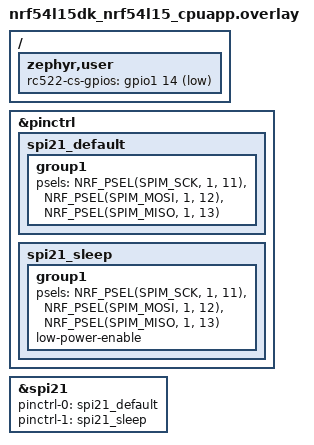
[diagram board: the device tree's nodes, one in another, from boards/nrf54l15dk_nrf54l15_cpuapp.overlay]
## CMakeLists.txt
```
cmake_minimum_required(VERSION 3.20.0)
find_package(Zephyr REQUIRED HINTS $ENV{ZEPHYR_BASE})
project(rune_nfc_uid_reader)

target_sources(app PRIVATE src/main.c src/rc522.c src/pn532.c)
```

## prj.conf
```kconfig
CONFIG_GPIO=y
CONFIG_SPI=y
CONFIG_I2C=y
CONFIG_PRINTK=y
CONFIG_CONSOLE=y
CONFIG_UART_CONSOLE=y
CONFIG_MAIN_STACK_SIZE=2048
```

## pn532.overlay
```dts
/*
 * Alternative wiring: PN532 reader on I2C21.
 * Use it by adding this file as an "Extra Devicetree overlay" in the
 * VS Code build configuration (or: west build ... -- -DEXTRA_DTC_OVERLAY_FILE=pn532.overlay).
 *
 * Set the PN532 module's switches to I2C mode (red "PN532 NFC V3" board:
 * switch 1 = ON, switch 2 = OFF), then power-cycle it.
 *
 *   PN532 pin  ->  nRF54L15 DK pin
 *   SCL        ->  P1.11
 *   SDA        ->  P1.12
 *   VCC        ->  VDD (3.3 V)
 *   GND        ->  GND
 *
 * IMPORTANT: set the DK's VDD to 3.3 V in nRF Connect "Board Configurator".
 */

&spi21 {
	status = "disabled";
};

&pinctrl {
	i2c21_default: i2c21_default {
		group1 {
			psels = <NRF_PSEL(TWIM_SCL, 1, 11)>,
				<NRF_PSEL(TWIM_SDA, 1, 12)>;
			bias-pull-up;
		};
	};

	i2c21_sleep: i2c21_sleep {
		group1 {
			psels = <NRF_PSEL(TWIM_SCL, 1, 11)>,
				<NRF_PSEL(TWIM_SDA, 1, 12)>;
			low-power-enable;
		};
	};
};

&i2c21 {
	status = "okay";
	pinctrl-0 = <&i2c21_default>;
	pinctrl-1 = <&i2c21_sleep>;
	pinctrl-names = "default", "sleep";
	clock-frequency = <I2C_BITRATE_STANDARD>;
};
```

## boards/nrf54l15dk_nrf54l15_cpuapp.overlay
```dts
/*
 * Default wiring: MFRC522 ("RC522") reader on SPI21.
 *
 *   RC522 pin   ->  nRF54L15 DK pin
 *   SDA (=CS)   ->  P1.14
 *   SCK         ->  P1.11
 *   MOSI        ->  P1.12
 *   MISO        ->  P1.13   (shared with Button 0: don't press Button 0)
 *   RST         ->  VDD (3.3 V)  (just keep the chip out of reset)
 *   3.3V        ->  VDD
 *   GND         ->  GND
 *   IRQ         ->  not connected
 *
 * IMPORTANT: set the DK's VDD to 3.3 V in nRF Connect "Board Configurator"
 * first. The RC522 cannot see 1.8 V logic.
 */

/ {
	zephyr,user {
		rc522-cs-gpios = <&gpio1 14 GPIO_ACTIVE_LOW>;
	};
};

&pinctrl {
	spi21_default: spi21_default {
		group1 {
			psels = <NRF_PSEL(SPIM_SCK, 1, 11)>,
				<NRF_PSEL(SPIM_MOSI, 1, 12)>,
				<NRF_PSEL(SPIM_MISO, 1, 13)>;
		};
	};

	spi21_sleep: spi21_sleep {
		group1 {
			psels = <NRF_PSEL(SPIM_SCK, 1, 11)>,
				<NRF_PSEL(SPIM_MOSI, 1, 12)>,
				<NRF_PSEL(SPIM_MISO, 1, 13)>;
			low-power-enable;
		};
	};
};

&spi21 {
	status = "okay";
	pinctrl-0 = <&spi21_default>;
	pinctrl-1 = <&spi21_sleep>;
	pinctrl-names = "default", "sleep";
};
```

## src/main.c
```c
/*
 * Rune board, step 1: read the ID (UID) of an NFC tag and print it.
 *
 * Output on the DK's USB serial port (115200 baud):
 *   TAG 04A1B2C3D4E5F6     when a tag is placed on the reader
 *   REMOVED                when it is taken away
 * LED0 is on while a tag is on the reader.
 */
#include <zephyr/kernel.h>
#include <zephyr/devicetree.h>
#include <zephyr/drivers/gpio.h>
#include <zephyr/sys/printk.h>
#include <string.h>
#include "nfc_reader.h"

#define POLL_MS     100
#define MISSES_GONE 3   /* polls without the tag before we call it removed */

static const struct gpio_dt_spec led = GPIO_DT_SPEC_GET(DT_ALIAS(led0), gpios);

static void print_uid(const uint8_t *uid, int len)
{
	printk("TAG ");
	for (int i = 0; i < len; i++) {
		printk("%02X", uid[i]);
	}
	printk("\n");
}

int main(void)
{
	uint8_t uid[10], last_uid[10];
	int last_len = 0;
	int misses = 0;

	gpio_pin_configure_dt(&led, GPIO_OUTPUT_INACTIVE);
	printk("\nRune NFC UID reader, using %s\n", nfc_reader_name());

	while (nfc_reader_init() != 0) {
		printk("Reader not found. Check wiring and that VDD is 3.3 V. Retrying...\n");
		k_msleep(2000);
	}
	printk("Reader ready. Put a tag on it.\n");

	while (true) {
		int len = nfc_reader_poll(uid, sizeof(uid));

		if (len > 0) {
			misses = 0;
			if (len != last_len || memcmp(uid, last_uid, len) != 0) {
				print_uid(uid, len);
				memcpy(last_uid, uid, len);
				last_len = len;
				gpio_pin_set_dt(&led, 1);
			}
		} else if (last_len > 0 && ++misses >= MISSES_GONE) {
			printk("REMOVED\n");
			last_len = 0;
			gpio_pin_set_dt(&led, 0);
		}
		k_msleep(POLL_MS);
	}
	return 0;
}
```

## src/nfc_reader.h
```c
#ifndef NFC_READER_H_
#define NFC_READER_H_

#include <stddef.h>
#include <stdint.h>

/* The PN532 driver is used when i2c21 is enabled (pn532.overlay), otherwise RC522. */
#define USE_PN532 DT_NODE_HAS_STATUS(DT_NODELABEL(i2c21), okay)

/* Returns 0 on success, negative errno if the reader does not answer. */
int nfc_reader_init(void);

/*
 * Looks for one ISO14443-A tag (NTAG, MIFARE Ultralight/Classic, ...).
 * Returns the UID length (4, 7 or 10) and fills uid, or 0 if no tag is there.
 */
int nfc_reader_poll(uint8_t *uid, size_t max_len);

const char *nfc_reader_name(void);

#endif
```

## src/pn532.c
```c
/* Minimal PN532 driver over I2C: reads the UID of one ISO14443-A tag. */
#include <zephyr/devicetree.h>
#include "nfc_reader.h"

#if USE_PN532

#include <errno.h>
#include <string.h>
#include <zephyr/kernel.h>
#include <zephyr/drivers/i2c.h>
#include <zephyr/sys/printk.h>

#define PN532_ADDR 0x24

static const struct device *i2c = DEVICE_DT_GET(DT_NODELABEL(i2c21));

static int write_frame(const uint8_t *data, size_t len)
{
	uint8_t f[40];
	size_t i = 0;
	uint8_t l = (uint8_t)(len + 1);
	uint8_t sum = 0xD4;

	if (len > sizeof(f) - 9) {
		return -EINVAL;
	}
	f[i++] = 0x00;
	f[i++] = 0x00;
	f[i++] = 0xFF;
	f[i++] = l;
	f[i++] = (uint8_t)(~l + 1);
	f[i++] = 0xD4; /* host -> PN532 */
	for (size_t j = 0; j < len; j++) {
		f[i++] = data[j];
		sum += data[j];
	}
	f[i++] = (uint8_t)(~sum + 1);
	f[i++] = 0x00;
	return i2c_write(i2c, f, i, PN532_ADDR);
}

static int wait_ready(int timeout_ms)
{
	int64_t end = k_uptime_get() + timeout_ms;
	uint8_t status;

	while (k_uptime_get() < end) {
		if (i2c_read(i2c, &status, 1, PN532_ADDR) == 0 && (status & 0x01)) {
			return 0;
		}
		k_msleep(2);
	}
	return -ETIMEDOUT;
}

/* Sends a command, returns number of response data bytes copied to resp (after D5 cmd+1). */
static int command(const uint8_t *cmd, size_t len, uint8_t *resp, size_t rmax, int timeout_ms)
{
	static const uint8_t ack_ok[6] = { 0x00, 0x00, 0xFF, 0x00, 0xFF, 0x00 };
	uint8_t ack[7];
	uint8_t buf[48];

	if (write_frame(cmd, len)) {
		return -EIO;
	}
	if (wait_ready(30)) {
		return -ETIMEDOUT;
	}
	if (i2c_read(i2c, ack, sizeof(ack), PN532_ADDR) || memcmp(&ack[1], ack_ok, 6)) {
		return -EIO;
	}
	if (wait_ready(timeout_ms)) {
		return -ETIMEDOUT;
	}
	if (i2c_read(i2c, buf, sizeof(buf), PN532_ADDR)) {
		return -EIO;
	}
	/* buf: status, 00 00 FF, LEN, LCS, D5, cmd+1, data... */
	if (buf[1] != 0x00 || buf[2] != 0x00 || buf[3] != 0xFF) {
		return -EIO;
	}
	if (buf[6] != 0xD5 || buf[7] != (uint8_t)(cmd[0] + 1) || buf[4] < 2) {
		return -EIO;
	}

	size_t dlen = buf[4] - 2;

	if (dlen > sizeof(buf) - 8) {
		dlen = sizeof(buf) - 8;
	}
	if (dlen > rmax) {
		dlen = rmax;
	}
	memcpy(resp, &buf[8], dlen);
	return (int)dlen;
}

int nfc_reader_init(void)
{
	uint8_t resp[8];
	int n = -1;

	if (!device_is_ready(i2c)) {
		return -ENODEV;
	}

	/* The first transfer may only wake the chip up, so retry. */
	for (int i = 0; i < 5 && n < 0; i++) {
		static const uint8_t get_fw[] = { 0x02 };

		n = command(get_fw, sizeof(get_fw), resp, sizeof(resp), 100);
		if (n < 0) {
			k_msleep(50);
		}
	}
	if (n < 4) {
		return -EIO;
	}
	printk("PN5%02X firmware %d.%d\n", resp[0], resp[1], resp[2]);

	static const uint8_t sam[] = { 0x14, 0x01, 0x14, 0x01 };       /* SAMConfiguration: normal */
	static const uint8_t retries[] = { 0x32, 0x05, 0xFF, 0x01, 0x02 }; /* don't wait forever for a tag */

	if (command(sam, sizeof(sam), resp, sizeof(resp), 100) < 0 ||
	    command(retries, sizeof(retries), resp, sizeof(resp), 100) < 0) {
		return -EIO;
	}
	return 0;
}

int nfc_reader_poll(uint8_t *uid, size_t max_len)
{
	static const uint8_t field_off[] = { 0x32, 0x01, 0x00 };
	static const uint8_t field_on[] = { 0x32, 0x01, 0x03 };
	static const uint8_t list[] = { 0x4A, 0x01, 0x00 }; /* 1 target, 106 kbps type A */
	uint8_t resp[24];

	/* Switch the field off and on so a tag that stays on the reader is seen again. */
	command(field_off, sizeof(field_off), resp, sizeof(resp), 50);
	k_msleep(5);
	command(field_on, sizeof(field_on), resp, sizeof(resp), 50);

	int n = command(list, sizeof(list), resp, sizeof(resp), 200);

	/* resp: NbTg, Tg, ATQA(2), SAK, UIDlen, UID... */
	if (n < 6 || resp[0] == 0) {
		return 0;
	}

	size_t len = resp[5];

	if (len > max_len || 6 + len > (size_t)n) {
		return 0;
	}
	memcpy(uid, &resp[6], len);
	return (int)len;
}

const char *nfc_reader_name(void)
{
	return "PN532 (I2C)";
}

#endif /* USE_PN532 */
```

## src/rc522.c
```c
/* Minimal MFRC522 (RC522) driver: reads the UID of one ISO14443-A tag. */
#include <zephyr/devicetree.h>
#include "nfc_reader.h"

#if !USE_PN532

#include <errno.h>
#include <zephyr/kernel.h>
#include <zephyr/drivers/spi.h>
#include <zephyr/drivers/gpio.h>
#include <zephyr/sys/printk.h>

/* Registers */
#define CommandReg    0x01
#define ComIrqReg     0x04
#define DivIrqReg     0x05
#define ErrorReg      0x06
#define FIFODataReg   0x09
#define FIFOLevelReg  0x0A
#define ControlReg    0x0C
#define BitFramingReg 0x0D
#define CollReg       0x0E
#define ModeReg       0x11
#define TxModeReg     0x12
#define RxModeReg     0x13
#define TxControlReg  0x14
#define TxASKReg      0x15
#define ModWidthReg   0x24
#define TModeReg      0x2A
#define TPrescalerReg 0x2B
#define TReloadRegH   0x2C
#define TReloadRegL   0x2D
#define VersionReg    0x37

/* Commands */
#define CMD_IDLE       0x00
#define CMD_TRANSCEIVE 0x0C
#define CMD_SOFTRESET  0x0F

static const struct device *spi = DEVICE_DT_GET(DT_NODELABEL(spi21));
static const struct gpio_dt_spec cs = GPIO_DT_SPEC_GET(DT_PATH(zephyr_user), rc522_cs_gpios);
static const struct spi_config spi_cfg = {
	.frequency = 4000000,
	.operation = SPI_WORD_SET(8) | SPI_TRANSFER_MSB, /* controller, mode 0 */
	.slave = 0,
};

static int xfer(uint8_t *tx, uint8_t *rx, size_t len)
{
	struct spi_buf tb = { .buf = tx, .len = len };
	struct spi_buf rb = { .buf = rx, .len = len };
	struct spi_buf_set ts = { .buffers = &tb, .count = 1 };
	struct spi_buf_set rs = { .buffers = &rb, .count = 1 };

	gpio_pin_set_dt(&cs, 1);
	int err = spi_transceive(spi, &spi_cfg, &ts, &rs);
	gpio_pin_set_dt(&cs, 0);
	return err;
}

static void wr(uint8_t reg, uint8_t val)
{
	uint8_t tx[2] = { (reg << 1) & 0x7E, val };
	uint8_t rx[2];

	xfer(tx, rx, 2);
}

static uint8_t rd(uint8_t reg)
{
	uint8_t tx[2] = { ((reg << 1) & 0x7E) | 0x80, 0 };
	uint8_t rx[2] = { 0 };

	xfer(tx, rx, 2);
	return rx[1];
}

static void set_bits(uint8_t reg, uint8_t mask) { wr(reg, rd(reg) | mask); }
static void clr_bits(uint8_t reg, uint8_t mask) { wr(reg, rd(reg) & ~mask); }

/* ISO14443-A CRC */
static void crc_a(const uint8_t *d, size_t n, uint8_t out[2])
{
	uint16_t crc = 0x6363;

	while (n--) {
		uint8_t ch = *d++ ^ (uint8_t)(crc & 0xFF);
		ch ^= (uint8_t)(ch << 4);
		crc = (crc >> 8) ^ ((uint16_t)ch << 8) ^ ((uint16_t)ch << 3) ^ ((uint16_t)ch >> 4);
	}
	out[0] = crc & 0xFF;
	out[1] = crc >> 8;
}

static int transceive(const uint8_t *send, size_t slen, uint8_t *back, size_t *blen,
		      uint8_t last_bits)
{
	wr(CommandReg, CMD_IDLE);
	wr(ComIrqReg, 0x7F);      /* clear irqs */
	wr(FIFOLevelReg, 0x80);   /* flush FIFO */
	for (size_t i = 0; i < slen; i++) {
		wr(FIFODataReg, send[i]);
	}
	wr(BitFramingReg, last_bits & 0x07);
	wr(CommandReg, CMD_TRANSCEIVE);
	set_bits(BitFramingReg, 0x80); /* StartSend */

	int64_t deadline = k_uptime_get() + 40;

	while (true) {
		uint8_t irq = rd(ComIrqReg);

		if (irq & 0x30) {        /* RxIRq | IdleIRq */
			break;
		}
		if (irq & 0x01) {        /* TimerIRq: nobody answered */
			return -ETIMEDOUT;
		}
		if (k_uptime_get() > deadline) {
			return -ETIMEDOUT;
		}
	}
	clr_bits(BitFramingReg, 0x80);

	uint8_t err = rd(ErrorReg);

	if (err & 0x13) {                /* BufferOvfl | ParityErr | ProtocolErr */
		return -EIO;
	}
	if (err & 0x08) {                /* collision: more than one tag */
		return -EBUSY;
	}

	uint8_t n = rd(FIFOLevelReg);

	if (n > *blen) {
		n = *blen;
	}
	for (uint8_t i = 0; i < n; i++) {
		back[i] = rd(FIFODataReg);
	}
	*blen = n;
	return 0;
}

int nfc_reader_init(void)
{
	if (!device_is_ready(spi) || !gpio_is_ready_dt(&cs)) {
		return -ENODEV;
	}
	gpio_pin_configure_dt(&cs, GPIO_OUTPUT_INACTIVE);

	wr(CommandReg, CMD_SOFTRESET);
	k_msleep(50);

	uint8_t ver = rd(VersionReg);

	printk("RC522 version register: 0x%02X (expected 0x91, 0x92 or 0x88/0x12 for clones)\n", ver);
	if (ver == 0x00 || ver == 0xFF) {
		return -EIO;
	}

	wr(TxModeReg, 0x00);
	wr(RxModeReg, 0x00);
	wr(ModWidthReg, 0x26);
	wr(TModeReg, 0x80);      /* timer starts automatically after sending */
	wr(TPrescalerReg, 0xA9); /* ~40 kHz timer */
	wr(TReloadRegH, 0x03);   /* 1000 ticks = 25 ms timeout */
	wr(TReloadRegL, 0xE8);
	wr(TxASKReg, 0x40);      /* 100% ASK */
	wr(ModeReg, 0x3D);       /* CRC preset 0x6363 */
	set_bits(TxControlReg, 0x03); /* antenna on */
	return 0;
}

int nfc_reader_poll(uint8_t *uid, size_t max_len)
{
	static const uint8_t sel_cmd[3] = { 0x93, 0x95, 0x97 };
	uint8_t atqa[2];
	size_t n = sizeof(atqa);
	uint8_t wupa = 0x52; /* WUPA also wakes tags we halted last time */
	size_t len = 0;

	clr_bits(CollReg, 0x80);
	if (transceive(&wupa, 1, atqa, &n, 7) || n != 2) {
		return 0;
	}

	for (int lvl = 0; lvl < 3; lvl++) {
		uint8_t ac[2] = { sel_cmd[lvl], 0x20 };
		uint8_t b[5];

		n = sizeof(b);
		clr_bits(CollReg, 0x80);
		if (transceive(ac, 2, b, &n, 0) || n != 5) {
			return 0;
		}
		if ((b[0] ^ b[1] ^ b[2] ^ b[3]) != b[4]) {
			return 0; /* bad BCC */
		}

		uint8_t sel[9] = { sel_cmd[lvl], 0x70, b[0], b[1], b[2], b[3], b[4] };
		uint8_t sak[3];

		crc_a(sel, 7, &sel[7]);
		n = sizeof(sak);
		if (transceive(sel, 9, sak, &n, 0) || n != 3) {
			return 0;
		}

		if (b[0] == 0x88) {             /* cascade tag: UID continues */
			for (int i = 1; i < 4 && len < max_len; i++) {
				uid[len++] = b[i];
			}
		} else {
			for (int i = 0; i < 4 && len < max_len; i++) {
				uid[len++] = b[i];
			}
			break;
		}
	}

	/* HLTA: put the tag to sleep so the next WUPA starts fresh. No reply expected. */
	uint8_t hlt[4] = { 0x50, 0x00 };
	uint8_t dummy[4];

	crc_a(hlt, 2, &hlt[2]);
	n = sizeof(dummy);
	transceive(hlt, 4, dummy, &n, 0);

	return (int)len;
}

const char *nfc_reader_name(void)
{
	return "RC522 (SPI)";
}

#endif /* !USE_PN532 */
```
